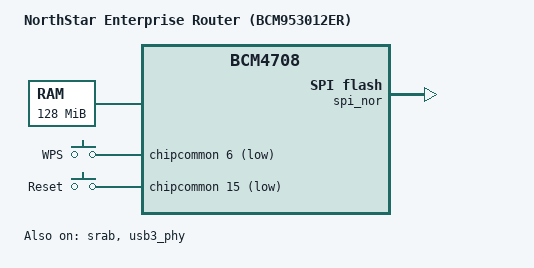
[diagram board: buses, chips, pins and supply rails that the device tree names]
/dts-v1/;
#include "bcm4708.dtsi"
#include "bcm5301x-nand-cs0-bch8.dtsi"
/ {
	model = "NorthStar Enterprise Router (BCM953012ER)";
	compatible = "brcm,bcm953012er", "brcm,bcm53012", "brcm,bcm4708";
	memory@0 {
		device_type = "memory";
		reg = <0x00000000 0x8000000>;
	};
	gpio-keys {
		compatible = "gpio-keys";
		button-wps {
			label = "WPS";
			linux,code = <KEY_WPS_BUTTON>;
			gpios = <&chipcommon 6 GPIO_ACTIVE_LOW>;
		};
		button-restart {
			label = "Reset";
			linux,code = <KEY_RESTART>;
			gpios = <&chipcommon 15 GPIO_ACTIVE_LOW>;
		};
	};
};
&spi_nor {
	status = "okay";
};
&srab {
	status = "okay";
	ports {
		port@0 {
			reg = <0>;
			label = "port0";
		};
		port@1 {
			reg = <1>;
			label = "port1";
		};
		port@5 {
			reg = <5>;
			label = "cpu";
			ethernet = <&gmac0>;
		};
		port@7 {
			status = "disabled";
		};
		port@8 {
			status = "disabled";
		};
	};
};
&usb3_phy {
	status = "okay";
};
